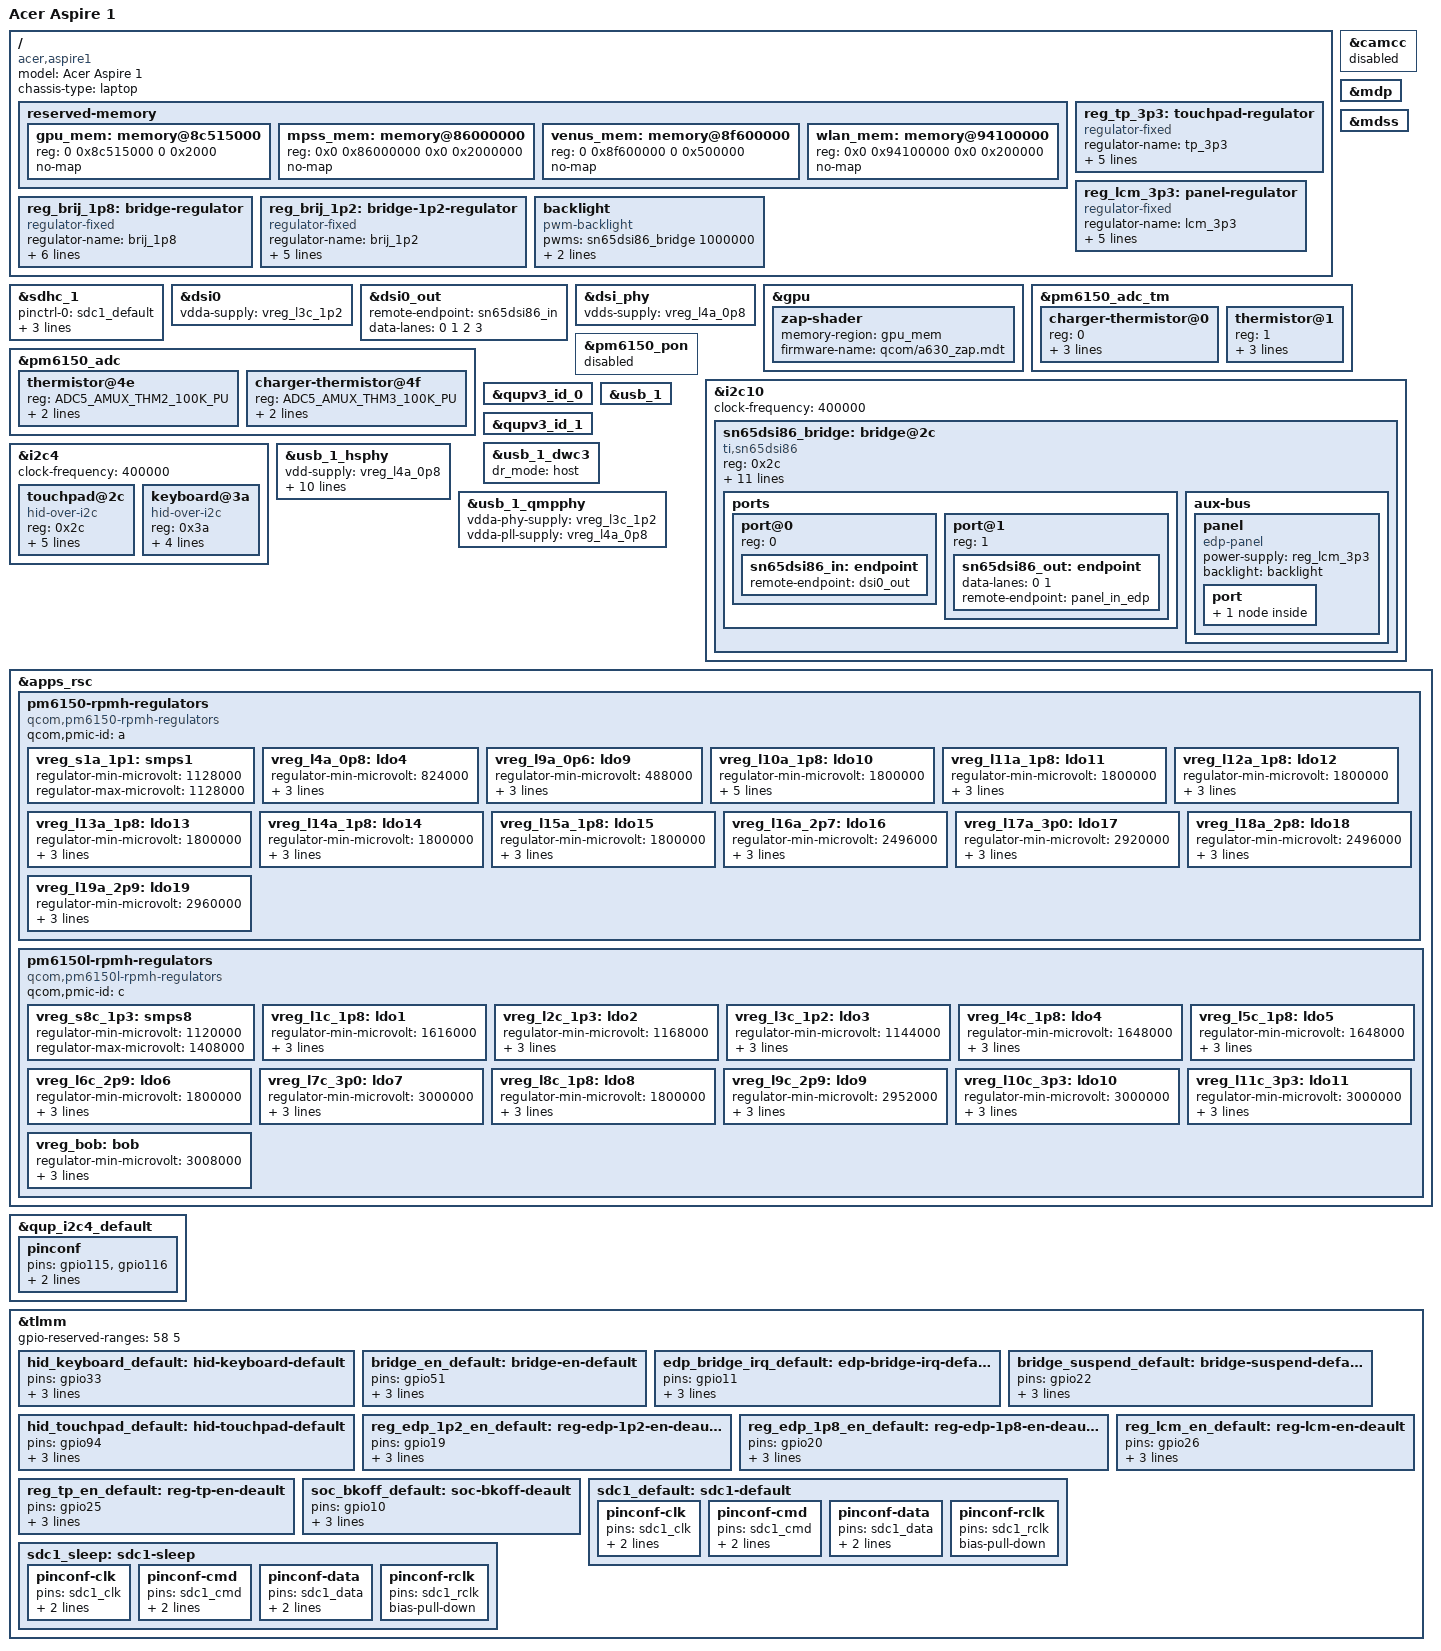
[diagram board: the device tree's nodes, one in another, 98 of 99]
// SPDX-License-Identifier: BSD-3-Clause

/dts-v1/;

#include <dt-bindings/gpio/gpio.h>
#include <dt-bindings/regulator/qcom,rpmh-regulator.h>

#include "sc7180.dtsi"

#include "pm6150.dtsi"
#include "pm6150l.dtsi"

/ {
	model = "Acer Aspire 1";
	compatible = "acer,aspire1", "qcom,sc7180";
	chassis-type = "laptop";
	/* Aspire 1 A114-61 series, model no. N20Q7 */

	reserved-memory {

		gpu_mem: memory@8c515000 {
			reg = <0 0x8c515000 0 0x2000>;
			no-map;
		};

		mpss_mem: memory@86000000 {
			reg = <0x0 0x86000000 0x0 0x2000000>;
			no-map;
		};

		venus_mem: memory@8f600000 {
			reg = <0 0x8f600000 0 0x500000>;
			no-map;
		};

		wlan_mem: memory@94100000 {
			reg = <0x0 0x94100000 0x0 0x200000>;
			no-map;
		};
	};

	reg_tp_3p3: touchpad-regulator {
		compatible = "regulator-fixed";
		regulator-name = "tp_3p3";
		regulator-min-microvolt = <3300000>;
		regulator-max-microvolt = <3300000>;

		gpio = <&tlmm 25 GPIO_ACTIVE_HIGH>;
		enable-active-high;

		pinctrl-names = "default";
		pinctrl-0 = <&reg_tp_en_default>;
	};

	reg_lcm_3p3: panel-regulator {
		compatible = "regulator-fixed";
		regulator-name = "lcm_3p3";
		regulator-min-microvolt = <3300000>;
		regulator-max-microvolt = <3300000>;

		gpio = <&tlmm 26 GPIO_ACTIVE_HIGH>;
		enable-active-high;

		pinctrl-names = "default";
		pinctrl-0 = <&reg_lcm_en_default>;
	};

	reg_brij_1p8: bridge-regulator {
		compatible = "regulator-fixed";
		regulator-name = "brij_1p8";
		regulator-min-microvolt = <1800000>;
		regulator-max-microvolt = <1800000>;

		vin-supply = <&vreg_l8c_1p8>;

		gpio = <&tlmm 20 GPIO_ACTIVE_HIGH>;
		enable-active-high;

		pinctrl-names = "default";
		pinctrl-0 = <&reg_edp_1p8_en_default>;
	};

	reg_brij_1p2: bridge-1p2-regulator {
		compatible = "regulator-fixed";
		regulator-name = "brij_1p2";
		regulator-min-microvolt = <1200000>;
		regulator-max-microvolt = <1200000>;

		gpio = <&tlmm 19 GPIO_ACTIVE_HIGH>;
		enable-active-high;

		pinctrl-names = "default";
		pinctrl-0 = <&reg_edp_1p2_en_default>;
	};

	backlight: backlight {
		compatible = "pwm-backlight";
		pwms = <&sn65dsi86_bridge 1000000>;
		enable-gpios = <&tlmm 10 GPIO_ACTIVE_HIGH>;

		pinctrl-names = "default";
		pinctrl-0 = <&soc_bkoff_default>;
	};
};

&camcc {
	status = "disabled";
};

&sdhc_1 {
	status = "okay";

	pinctrl-names = "default", "sleep";
	pinctrl-0 = <&sdc1_default>;
	pinctrl-1 = <&sdc1_sleep>;
	vmmc-supply = <&vreg_l19a_2p9>;
	vqmmc-supply = <&vreg_l12a_1p8>;
};

&dsi0 {
	status = "okay";
	vdda-supply = <&vreg_l3c_1p2>;
};

&dsi0_out {
	remote-endpoint = <&sn65dsi86_in>;
	data-lanes = <0 1 2 3>;
};

&dsi_phy {
	status = "okay";
	vdds-supply = <&vreg_l4a_0p8>;
};

&mdp {
	status = "okay";
};

&mdss {
	status = "okay";
};

&gpu {
	status = "okay";
	zap-shader {
		memory-region = <&gpu_mem>;
		firmware-name = "qcom/a630_zap.mdt";
	};
};

&pm6150_adc {
	thermistor@4e {
		reg = <ADC5_AMUX_THM2_100K_PU>;
		qcom,ratiometric;
		qcom,hw-settle-time = <200>;
	};

	charger-thermistor@4f {
		reg = <ADC5_AMUX_THM3_100K_PU>;
		qcom,ratiometric;
		qcom,hw-settle-time = <200>;
	};
};

&pm6150_adc_tm {
	status = "okay";

	charger-thermistor@0 {
		reg = <0>;
		io-channels = <&pm6150_adc ADC5_AMUX_THM3_100K_PU>;
		qcom,ratiometric;
		qcom,hw-settle-time-us = <200>;
	};

	thermistor@1 {
		reg = <1>;
		io-channels = <&pm6150_adc ADC5_AMUX_THM2_100K_PU>;
		qcom,ratiometric;
		qcom,hw-settle-time-us = <200>;
	};
};

&pm6150_pon {
	status = "disabled";
};

&i2c10 {
	status = "okay";
	clock-frequency = <400000>;

	sn65dsi86_bridge: bridge@2c {
		compatible = "ti,sn65dsi86";
		reg = <0x2c>;
		pinctrl-names = "default";
		pinctrl-0 = <&bridge_en_default>,
			<&edp_bridge_irq_default>/*,
			<&bridge_suspend_default>*/;
		gpio-controller;
		#gpio-cells = <2>;
		#pwm-cells = <1>;

		interrupt-parent = <&tlmm>;
		interrupts = <11 IRQ_TYPE_LEVEL_HIGH>;

		enable-gpios = <&tlmm 51 GPIO_ACTIVE_HIGH>;
		//suspend-gpios = <&tlmm 22 GPIO_ACTIVE_LOW>;

		vpll-supply = <&reg_brij_1p8>;
		vccio-supply = <&reg_brij_1p8>;
		vcca-supply = <&reg_brij_1p2>;
		vcc-supply = <&reg_brij_1p2>;

		clocks = <&rpmhcc RPMH_LN_BB_CLK3>;
		clock-names = "refclk";

		//no-hpd;

		ports {
			#address-cells = <1>;
			#size-cells = <0>;

			port@0 {
				reg = <0>;
				sn65dsi86_in: endpoint {
					remote-endpoint = <&dsi0_out>;
				};
			};

			port@1 {
				reg = <1>;
				sn65dsi86_out: endpoint {
					data-lanes = <0 1>;
					remote-endpoint = <&panel_in_edp>;
				};
			};
		};

		aux-bus {
			panel: panel {
				compatible = "edp-panel";
				power-supply = <&reg_lcm_3p3>;
				backlight = <&backlight>;
				//hpd-gpios = <&sn65dsi86_bridge 2 GPIO_ACTIVE_HIGH>;

				port {
					panel_in_edp: endpoint {
						remote-endpoint = <&sn65dsi86_out>;
					};
				};
			};
		};
	};
};

&i2c4 {
	status = "okay";
	clock-frequency = <400000>;

	/*
	 * NOTE: DSDT defines two possible touchpads, other one is
	 *
	 * reg = <0x15>;
	 * hid-descr-addr = <0x1>;
	 */

	touchpad@2c {
		compatible = "hid-over-i2c";
		reg = <0x2c>;
		hid-descr-addr = <0x20>;

		vdd-supply = <&reg_tp_3p3>;

		interrupts-extended = <&tlmm 94 IRQ_TYPE_LEVEL_LOW>;

		pinctrl-names = "default";
		pinctrl-0 = <&hid_touchpad_default>;
	};

	keyboard@3a {
		compatible = "hid-over-i2c";
		reg = <0x3a>;
		hid-descr-addr = <0x1>;

		interrupts-extended = <&tlmm 33 IRQ_TYPE_LEVEL_LOW>;

		pinctrl-names = "default";
		pinctrl-0 = <&hid_keyboard_default>;
	};
};

&qupv3_id_0 {
	status = "okay";
};

&qupv3_id_1 {
	status = "okay";
};

&usb_1 {
	status = "okay";
};

&usb_1_dwc3 {
	dr_mode = "host";
};

&usb_1_hsphy {
	status = "okay";
	vdd-supply = <&vreg_l4a_0p8>;
	vdda-pll-supply = <&vreg_l11a_1p8>;
	vdda-phy-dpdm-supply = <&vreg_l17a_3p0>;
	qcom,imp-res-offset-value = <8>;
	qcom,preemphasis-level = <QUSB2_V2_PREEMPHASIS_15_PERCENT>;
	qcom,preemphasis-width = <QUSB2_V2_PREEMPHASIS_WIDTH_HALF_BIT>;
	qcom,bias-ctrl-value = <0x22>;
	qcom,charge-ctrl-value = <3>;
	qcom,hsdisc-trim-value = <0>;
};

&usb_1_qmpphy {
	status = "okay";
	vdda-phy-supply = <&vreg_l3c_1p2>;
	vdda-pll-supply = <&vreg_l4a_0p8>;
};

&apps_rsc {
	pm6150-rpmh-regulators {
		compatible = "qcom,pm6150-rpmh-regulators";
		qcom,pmic-id = "a";

		vreg_s1a_1p1: smps1 {
			regulator-min-microvolt = <1128000>;
			regulator-max-microvolt = <1128000>;
		};

		vreg_l4a_0p8: ldo4 { // acpi p88
			regulator-min-microvolt = <824000>;
			regulator-max-microvolt = <928000>;
			regulator-initial-mode = <RPMH_REGULATOR_MODE_HPM>;
		};

		vreg_l9a_0p6: ldo9 { // acpi p664
			regulator-min-microvolt = <488000>;
			regulator-max-microvolt = <800000>;
			regulator-initial-mode = <RPMH_REGULATOR_MODE_HPM>;
		};

		vreg_l10a_1p8: ldo10 { // acpi 1p8 sx -> Vio
			regulator-min-microvolt = <1800000>;
			regulator-max-microvolt = <1800000>;
			regulator-initial-mode = <RPMH_REGULATOR_MODE_HPM>;

			regulator-always-on;
			regulator-boot-on;
		};

		vreg_l11a_1p8: ldo11 { // trogdor
			regulator-min-microvolt = <1800000>;
			regulator-max-microvolt = <1800000>;
			regulator-initial-mode = <RPMH_REGULATOR_MODE_HPM>;
		};

		vreg_l12a_1p8: ldo12 { // acpi 1p8
			regulator-min-microvolt = <1800000>;
			regulator-max-microvolt = <1800000>;
			regulator-initial-mode = <RPMH_REGULATOR_MODE_HPM>;
		};

		vreg_l13a_1p8: ldo13 { // sx 1p8 NC
			regulator-min-microvolt = <1800000>;
			regulator-max-microvolt = <1800000>;
			regulator-initial-mode = <RPMH_REGULATOR_MODE_HPM>;
		};

		vreg_l14a_1p8: ldo14 { // sx 1p8 NC
			regulator-min-microvolt = <1800000>;
			regulator-max-microvolt = <1800000>;
			regulator-initial-mode = <RPMH_REGULATOR_MODE_HPM>;
		};

		vreg_l15a_1p8: ldo15 { // acpi 1p8 sx -> acodec
			regulator-min-microvolt = <1800000>;
			regulator-max-microvolt = <1800000>;
			regulator-initial-mode = <RPMH_REGULATOR_MODE_HPM>;
		};

		vreg_l16a_2p7: ldo16 { // sx 2p7 NC
			regulator-min-microvolt = <2496000>;
			regulator-max-microvolt = <3304000>;
			regulator-initial-mode = <RPMH_REGULATOR_MODE_HPM>;
		};

		vreg_l17a_3p0: ldo17 { // acpi 3p088 sx NC
			regulator-min-microvolt = <2920000>;
			regulator-max-microvolt = <3232000>;
			regulator-initial-mode = <RPMH_REGULATOR_MODE_HPM>;
		};

		vreg_l18a_2p8: ldo18 { // sx 3p3 NC
			regulator-min-microvolt = <2496000>;
			regulator-max-microvolt = <3304000>;
			regulator-initial-mode = <RPMH_REGULATOR_MODE_HPM>;
		};

		vreg_l19a_2p9: ldo19 { // acpi 2p96
			regulator-min-microvolt = <2960000>;
			regulator-max-microvolt = <2960000>;
			regulator-initial-mode = <RPMH_REGULATOR_MODE_HPM>;
		};
	};

	pm6150l-rpmh-regulators {
		compatible = "qcom,pm6150l-rpmh-regulators";
		qcom,pmic-id = "c";

		vreg_s8c_1p3: smps8 { // sx 1p3 NC
			regulator-min-microvolt = <1120000>;
			regulator-max-microvolt = <1408000>;
		};

		vreg_l1c_1p8: ldo1 { // acpi 1p8
			regulator-min-microvolt = <1616000>;
			regulator-max-microvolt = <1984000>;
			regulator-initial-mode = <RPMH_REGULATOR_MODE_HPM>;
		};

		vreg_l2c_1p3: ldo2 { // acpi 1p304
			regulator-min-microvolt = <1168000>;
			regulator-max-microvolt = <1304000>;
			regulator-initial-mode = <RPMH_REGULATOR_MODE_HPM>;
		};

		vreg_l3c_1p2: ldo3 { // acpi 1p2
			regulator-min-microvolt = <1144000>;
			regulator-max-microvolt = <1304000>;
			regulator-initial-mode = <RPMH_REGULATOR_MODE_HPM>;
		};

		vreg_l4c_1p8: ldo4 { // sx 1p8 -> UIM1 (nc)
			regulator-min-microvolt = <1648000>;
			regulator-max-microvolt = <3304000>;
			regulator-initial-mode = <RPMH_REGULATOR_MODE_LPM>;
		};

		vreg_l5c_1p8: ldo5 { // sx 1p8 -> e-UIM (nc)
			regulator-min-microvolt = <1648000>;
			regulator-max-microvolt = <3304000>;
			regulator-initial-mode = <RPMH_REGULATOR_MODE_LPM>;
		};

		vreg_l6c_2p9: ldo6 { // sx 2p96 NC?
			regulator-min-microvolt = <1800000>;
			regulator-max-microvolt = <2950000>;
			regulator-initial-mode = <RPMH_REGULATOR_MODE_HPM>;
		};

		vreg_l7c_3p0: ldo7 { // sx 3p0 NC?
			regulator-min-microvolt = <3000000>;
			regulator-max-microvolt = <3312000>;
			regulator-initial-mode = <RPMH_REGULATOR_MODE_LPM>;
		};

		vreg_l8c_1p8: ldo8 { // acpi 1p8 sx -> BRIJ
			regulator-min-microvolt = <1800000>;
			regulator-max-microvolt = <1800000>;
			regulator-initial-mode = <RPMH_REGULATOR_MODE_HPM>;
		};

		vreg_l9c_2p9: ldo9 { // sx 2p95 NC
			regulator-min-microvolt = <2952000>;
			regulator-max-microvolt = <2952000>;
			regulator-initial-mode = <RPMH_REGULATOR_MODE_HPM>;
		};

		vreg_l10c_3p3: ldo10 { // acpi 3p304
			regulator-min-microvolt = <3000000>;
			regulator-max-microvolt = <3400000>;
			regulator-initial-mode = <RPMH_REGULATOR_MODE_HPM>;
		};

		vreg_l11c_3p3: ldo11 {
			regulator-min-microvolt = <3000000>;
			regulator-max-microvolt = <3400000>;
			regulator-initial-mode = <RPMH_REGULATOR_MODE_HPM>;
		};

		vreg_bob: bob {
			regulator-min-microvolt = <3008000>;
			regulator-max-microvolt = <3960000>;
			regulator-initial-mode = <RPMH_REGULATOR_MODE_AUTO>;
		};
	};
};

&qup_i2c4_default {
	pinconf {
		pins = "gpio115", "gpio116";
		drive-strength = <2>;

		/* Has external pullup */
		bias-disable;
	};
};

&tlmm {
	/*
	 * The TZ seem to protect those because some boards can have
	 * fingerprint sensor connected to this range. Not connected
	 * on this board
	 */
	gpio-reserved-ranges = <58 5>;

	hid_keyboard_default: hid-keyboard-default {
		pins = "gpio33";
		function = "gpio";
		drive-strength = <2>;
		bias-disable;
	};

	bridge_en_default: bridge-en-default {
		pins = "gpio51";
		function = "gpio";
		drive-strength = <16>;
		bias-disable;
	};

	edp_bridge_irq_default: edp-bridge-irq-default {
		pins = "gpio11";
		function = "gpio";
		drive-strength = <2>;
		bias-pull-down;
	};

	bridge_suspend_default: bridge-suspend-default {
		pins = "gpio22";
		function = "gpio";
		drive-strength = <16>;
		bias-pull-up;
	};

	hid_touchpad_default: hid-touchpad-default {
		pins = "gpio94";
		function = "gpio";
		drive-strength = <2>;
		bias-disable;
	};

	reg_edp_1p2_en_default: reg-edp-1p2-en-deault {
		pins = "gpio19";
		function = "gpio";
		drive-strength = <16>;
		bias-disable;
	};

	reg_edp_1p8_en_default: reg-edp-1p8-en-deault {
		pins = "gpio20";
		function = "gpio";
		drive-strength = <16>;
		bias-disable;
	};

	reg_lcm_en_default: reg-lcm-en-deault {
		pins = "gpio26";
		function = "gpio";
		drive-strength = <16>;
		bias-disable;
	};

	reg_tp_en_default: reg-tp-en-deault {
		pins = "gpio25";
		function = "gpio";
		drive-strength = <2>;
		bias-disable;
	};

	soc_bkoff_default: soc-bkoff-deault {
		pins = "gpio10";
		function = "gpio";
		drive-strength = <16>;
		bias-disable;
	};

	sdc1_default: sdc1-default {
		pinconf-clk {
			pins = "sdc1_clk";
			bias-disable;
			drive-strength = <16>;
		};

		pinconf-cmd {
			pins = "sdc1_cmd";
			bias-pull-up;
			drive-strength = <16>;
		};

		pinconf-data {
			pins = "sdc1_data";
			bias-pull-up;
			drive-strength = <16>;
		};

		pinconf-rclk {
			pins = "sdc1_rclk";
			bias-pull-down;
		};
	};

	sdc1_sleep: sdc1-sleep {
		pinconf-clk {
			pins = "sdc1_clk";
			bias-disable;
			drive-strength = <2>;
		};

		pinconf-cmd {
			pins = "sdc1_cmd";
			bias-pull-up;
			drive-strength = <2>;
		};

		pinconf-data {
			pins = "sdc1_data";
			bias-pull-up;
			drive-strength = <2>;
		};

		pinconf-rclk {
			pins = "sdc1_rclk";
			bias-pull-down;
		};
	};
};
